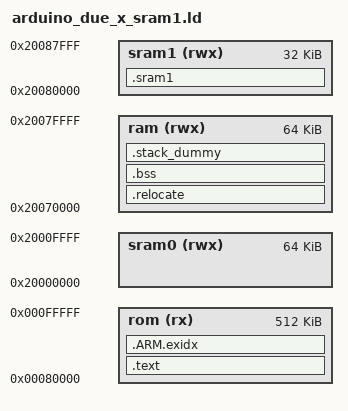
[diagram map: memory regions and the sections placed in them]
/*
 * Track A link map: the stock Due flash.ld with two changes.
 *
 * This exists so that Track A can pin the ADC capture ring to SRAM bank
 * 1, the same way Track B does in linker/sam3x8e_flash.ld. It is passed
 * with
 *
 *   --build-property build.ldscript=<relative path to here>
 *
 * because platform.txt links with "-T{build.variant.path}/{build.ldscript}"
 * and boards.txt sets build.ldscript to the stock script - an ordinary
 * build property, substitutable exactly like build.f_cpu.
 *
 * Nothing computes a relative path any more. cmake/track_a.cmake links
 * this script directly (#55), so the arduino-cli wrapper that had to
 * resolve it against the *installed variant directory* - and its
 * silence when it got that wrong - is gone with it.
 *
 * The two changes, both required and neither optional:
 *
 * 1. `ram` is shrunk from 96K to bank 0's 64K. The stock region spans
 *    0x20070000..0x20088000, which *includes* bank 1 - so .bss grows
 *    into the bank the DMA buffer is pinned to and lands on top of it
 *    with no diagnostic. It already did: before this script, the
 *    sketch's .bss ended at 0x20081B6C, 6.5 KB inside bank 1.
 *
 * 2. A `.sram1` output section over the (stock, already-declared) sram1
 *    region.
 *
 * The stack follows `ram` and therefore moves from the top of bank 1 to
 * the top of bank 0, which is deliberate: leaving it in bank 1 would put
 * every push and pop in the way of the PDC writes this separation exists
 * to protect. That leaves roughly 9 KB for stack and heap together,
 * which is the same budget Track B runs in.
 */
/* ----------------------------------------------------------------------------
 *         SAM Software Package License
 * ----------------------------------------------------------------------------
 * Copyright (c) 2012, Atmel Corporation
 *
 * All rights reserved.
 *
 * Redistribution and use in source and binary forms, with or without
 * modification, are permitted provided that the following condition is met:
 *
 * - Redistributions of source code must retain the above copyright notice,
 * this list of conditions and the disclaimer below.
 *
 * Atmel's name may not be used to endorse or promote products derived from
 * this software without specific prior written permission.
 *
 * DISCLAIMER: THIS SOFTWARE IS PROVIDED BY ATMEL "AS IS" AND ANY EXPRESS OR
 * IMPLIED WARRANTIES, INCLUDING, BUT NOT LIMITED TO, THE IMPLIED WARRANTIES OF
 * MERCHANTABILITY, FITNESS FOR A PARTICULAR PURPOSE AND NON-INFRINGEMENT ARE
 * DISCLAIMED. IN NO EVENT SHALL ATMEL BE LIABLE FOR ANY DIRECT, INDIRECT,
 * INCIDENTAL, SPECIAL, EXEMPLARY, OR CONSEQUENTIAL DAMAGES (INCLUDING, BUT NOT
 * LIMITED TO, PROCUREMENT OF SUBSTITUTE GOODS OR SERVICES; LOSS OF USE, DATA,
 * OR PROFITS; OR BUSINESS INTERRUPTION) HOWEVER CAUSED AND ON ANY THEORY OF
 * LIABILITY, WHETHER IN CONTRACT, STRICT LIABILITY, OR TORT (INCLUDING
 * NEGLIGENCE OR OTHERWISE) ARISING IN ANY WAY OUT OF THE USE OF THIS SOFTWARE,
 * EVEN IF ADVISED OF THE POSSIBILITY OF SUCH DAMAGE.
 * ----------------------------------------------------------------------------
 */

OUTPUT_FORMAT("elf32-littlearm", "elf32-littlearm", "elf32-littlearm")
OUTPUT_ARCH(arm)
SEARCH_DIR(.)

/* Memory Spaces Definitions */
MEMORY
{
	rom (rx)    : ORIGIN = 0x00080000, LENGTH = 0x00080000 /* Flash, 512K */
	sram0 (rwx) : ORIGIN = 0x20000000, LENGTH = 0x00010000 /* sram0, 64K */
	sram1 (rwx) : ORIGIN = 0x20080000, LENGTH = 0x00008000 /* sram1, 32K */
	ram (rwx)   : ORIGIN = 0x20070000, LENGTH = 0x00010000 /* bank 0, 64K */
}

/* Section Definitions */
SECTIONS
{
    .text :
    {
        . = ALIGN(4);
        _sfixed = .;
        KEEP(*(.vectors .vectors.*))
        *(.text .text.* .gnu.linkonce.t.*)
        *(.glue_7t) *(.glue_7)
        *(.rodata .rodata* .gnu.linkonce.r.*)
        *(.ARM.extab* .gnu.linkonce.armextab.*)

        /* Support C constructors, and C destructors in both user code
           and the C library. This also provides support for C++ code. */
        . = ALIGN(4);
        KEEP(*(.init))
        . = ALIGN(4);
        __preinit_array_start = .;
        KEEP (*(.preinit_array))
        __preinit_array_end = .;

        . = ALIGN(4);
        __init_array_start = .;
        KEEP (*(SORT(.init_array.*)))
        KEEP (*(.init_array))
        __init_array_end = .;

        . = ALIGN(0x4);
        KEEP (*crtbegin.o(.ctors))
        KEEP (*(EXCLUDE_FILE (*crtend.o) .ctors))
        KEEP (*(SORT(.ctors.*)))
        KEEP (*crtend.o(.ctors))

        . = ALIGN(4);
        KEEP(*(.fini))

        . = ALIGN(4);
        __fini_array_start = .;
        KEEP (*(.fini_array))
        KEEP (*(SORT(.fini_array.*)))
        __fini_array_end = .;

        KEEP (*crtbegin.o(.dtors))
        KEEP (*(EXCLUDE_FILE (*crtend.o) .dtors))
        KEEP (*(SORT(.dtors.*)))
        KEEP (*crtend.o(.dtors))

        . = ALIGN(4);
        _efixed = .;            /* End of text section */
    } > rom

    /* .ARM.exidx is sorted, so has to go in its own output section.  */
    PROVIDE_HIDDEN (__exidx_start = .);
    .ARM.exidx :
    {
      *(.ARM.exidx* .gnu.linkonce.armexidx.*)
    } > rom
    PROVIDE_HIDDEN (__exidx_end = .);

    . = ALIGN(4);
    _etext = .;

    .relocate : AT (_etext)
    {
        . = ALIGN(4);
        _srelocate = .;
        *(.ramfunc .ramfunc.*);
        *(.data .data.*);
        . = ALIGN(4);
        _erelocate = .;
    } > ram

    /* .bss section which is used for uninitialized data */
    .bss ALIGN(4) (NOLOAD) :
    {
        . = ALIGN(4);
        _sbss = . ;
        _szero = .;
        *(.bss .bss.*)
        *(COMMON)
        . = ALIGN(4);
        _ebss = . ;
        _ezero = .;
    } > ram

    . = ALIGN(4);
    _end = . ;

    /* .stack_dummy section doesn't contains any symbols. It is only
       used for linker to calculate size of stack sections, and assign
       values to stack symbols later */
    .stack_dummy :
    {
        *(.stack*)
    } > ram

    /* Set stack top to end of ram, and stack limit move down by
     * size of stack_dummy section */
    __StackTop = ORIGIN(ram) + LENGTH(ram);
    __StackLimit = __StackTop - SIZEOF(.stack_dummy);
    PROVIDE(_sstack = __StackLimit);
    PROVIDE(_estack = __StackTop);

    /* Last, so that the location counter - and with it _end, which is
       where syscalls_sam3.c's _sbrk() starts the heap - is still in
       bank 0. Nothing lands here unless explicitly placed: the region is
       reserved for the ADC capture ring, so that PDC writes and USB DMA
       reads are not arbitrating for the same bus matrix slave as
       everything else. Use __attribute__((section(".sram1"))). */
    .sram1 (NOLOAD) :
    {
        . = ALIGN(4);
        _ssram1 = .;
        *(.sram1 .sram1.*)
        . = ALIGN(4);
        _esram1 = .;
    } > sram1
}
